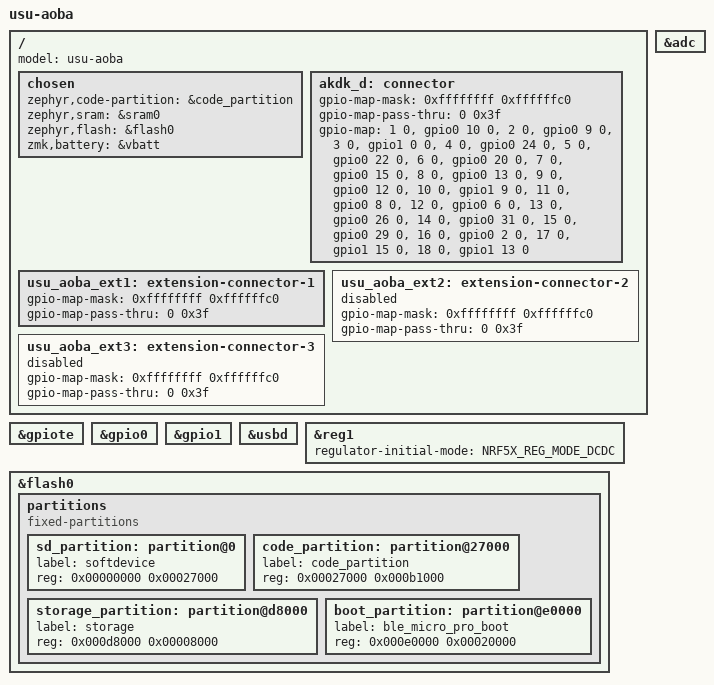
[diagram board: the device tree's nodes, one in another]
/*
 * Copyright (c) 2026 sekigon-gonnoc
 *
 * SPDX-License-Identifier: MIT
 */

/dts-v1/;

#include <nordic/nrf52840_qiaa.dtsi>
#include <common/nordic/nrf52840_uf2_boot_mode.dtsi>

#define USU_AOBA_EXTENSION_1 &usu_aoba_ext1
#define USU_AOBA_EXTENSION_2 &usu_aoba_ext2
#define USU_AOBA_EXTENSION_3 &usu_aoba_ext3

#define USU_AOBA_EXTENSION_1_GPIO(pin, flags) <USU_AOBA_EXTENSION_1 pin flags>
#define USU_AOBA_EXTENSION_2_GPIO(pin, flags) <USU_AOBA_EXTENSION_2 pin flags>
#define USU_AOBA_EXTENSION_3_GPIO(pin, flags) <USU_AOBA_EXTENSION_3 pin flags>

#define _USU_AOBA_EXTENSION_PSEL(port, pin, peripheral) \
	NRF_PSEL(peripheral, USU_AOBA_EXT##port##_PIN##pin##_PORT, \
		USU_AOBA_EXT##port##_PIN##pin##_NUMBER)
#define USU_AOBA_EXTENSION_PSEL(port, pin, peripheral) \
	_USU_AOBA_EXTENSION_PSEL(port, pin, peripheral)

#define USU_AOBA_EXTENSION_1_PSEL_PIN1(peripheral) USU_AOBA_EXTENSION_PSEL(1, 1, peripheral)
#define USU_AOBA_EXTENSION_1_PSEL_PIN2(peripheral) USU_AOBA_EXTENSION_PSEL(1, 2, peripheral)
#define USU_AOBA_EXTENSION_1_PSEL_PIN3(peripheral) USU_AOBA_EXTENSION_PSEL(1, 3, peripheral)
#define USU_AOBA_EXTENSION_1_PSEL_PIN4(peripheral) USU_AOBA_EXTENSION_PSEL(1, 4, peripheral)

#define USU_AOBA_EXTENSION_2_PSEL_PIN1(peripheral) USU_AOBA_EXTENSION_PSEL(2, 1, peripheral)
#define USU_AOBA_EXTENSION_2_PSEL_PIN2(peripheral) USU_AOBA_EXTENSION_PSEL(2, 2, peripheral)
#define USU_AOBA_EXTENSION_2_PSEL_PIN3(peripheral) USU_AOBA_EXTENSION_PSEL(2, 3, peripheral)
#define USU_AOBA_EXTENSION_2_PSEL_PIN4(peripheral) USU_AOBA_EXTENSION_PSEL(2, 4, peripheral)

#define USU_AOBA_EXTENSION_3_PSEL_PIN1(peripheral) USU_AOBA_EXTENSION_PSEL(3, 1, peripheral)
#define USU_AOBA_EXTENSION_3_PSEL_PIN2(peripheral) USU_AOBA_EXTENSION_PSEL(3, 2, peripheral)
#define USU_AOBA_EXTENSION_3_PSEL_PIN3(peripheral) USU_AOBA_EXTENSION_PSEL(3, 3, peripheral)
#define USU_AOBA_EXTENSION_3_PSEL_PIN4(peripheral) USU_AOBA_EXTENSION_PSEL(3, 4, peripheral)

/ {
    model = "usu-aoba";

    chosen {
        zephyr,code-partition = &code_partition;
        zephyr,sram = &sram0;
        zephyr,flash = &flash0;
        zmk,battery = &vbatt;
    };

	akdk_d: connector {
		#gpio-cells = <2>;
		gpio-map-mask = <0xffffffff 0xffffffc0>;
		gpio-map-pass-thru = <0 0x3f>;
		gpio-map
			= <1 0 &gpio0 10 0>
			, <2 0 &gpio0 9 0>	
			, <3 0 &gpio1 0 0>	
			, <4 0 &gpio0 24 0>
			, <5 0 &gpio0 22 0>
			, <6 0 &gpio0 20 0>
			, <7 0 &gpio0 15 0>
			, <8 0 &gpio0 13 0>
			, <9 0 &gpio0 12 0>	
			, <10 0 &gpio1 9 0>	
			, <11 0 &gpio0 8 0>
			, <12 0 &gpio0 6 0>
			, <13 0 &gpio0 26 0>
			, <14 0 &gpio0 31 0>
			, <15 0 &gpio0 29 0>
			, <16 0 &gpio0 2 0>
			, <17 0 &gpio1 15 0>
			, <18 0 &gpio1 13 0>
			;
	};

	usu_aoba_ext1: extension-connector-1 {
		#gpio-cells = <2>;
		gpio-map-mask = <0xffffffff 0xffffffc0>;
		gpio-map-pass-thru = <0 0x3f>;
	};

	usu_aoba_ext2: extension-connector-2 {
		#gpio-cells = <2>;
		gpio-map-mask = <0xffffffff 0xffffffc0>;
		gpio-map-pass-thru = <0 0x3f>;
		status = "disabled";
	};

	usu_aoba_ext3: extension-connector-3 {
		#gpio-cells = <2>;
		gpio-map-mask = <0xffffffff 0xffffffc0>;
		gpio-map-pass-thru = <0 0x3f>;
		status = "disabled";
	};
};

&adc {
    status = "okay";
};

&gpiote {
    status = "okay";
};

&gpio0 {
    status = "okay";
};

&gpio1 {
    status = "okay";
};

zephyr_udc0: &usbd {
    status = "okay";
};

&reg1 {
    regulator-initial-mode = <NRF5X_REG_MODE_DCDC>;
};

&flash0 {
    partitions {
        compatible = "fixed-partitions";
        #address-cells = <1>;
        #size-cells = <1>;

        sd_partition: partition@0 {
            label = "softdevice";
            reg = <0x00000000 0x00027000>;
        };

        code_partition: partition@27000 {
            label = "code_partition";
            reg = <0x00027000 0x000b1000>;
        };

        storage_partition: partition@d8000 {
            label = "storage";
            reg = <0x000d8000 0x00008000>;
        };

        boot_partition: partition@e0000 {
            label = "ble_micro_pro_boot";
            reg = <0x000e0000 0x00020000>;
        };
    };
};
